# STM32H7B0 register map
File version: 1.7
CPU: CM7 r0p1, little endian, MPU, FPU, 4 interrupt priority bits
Registers are 32-bit, read-write, reset 0x0 unless marked. A register's access mark holds for its fields unless they carry their own. Offsets are from the block's base; [hi:lo] are bit positions; lines under a group give offsets from that group; 'fields as' and 'values as' point back to an identical list.

## Flash (part 2 of 2) — Embedded Flash memory
Base 0x52002000
0x5C FLASH_CRCDATAR — FLASH CRC data register
  [31:0] CRC_DATA — CRC result
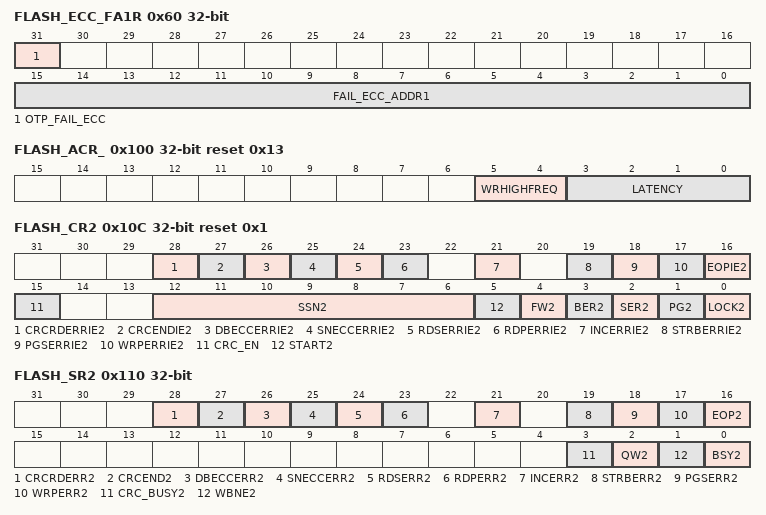
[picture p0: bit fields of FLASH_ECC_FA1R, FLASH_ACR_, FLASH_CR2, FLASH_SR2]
0x60 FLASH_ECC_FA1R ro
  [31] OTP_FAIL_ECC — OTP ECC error bit This bit is set to 1 when one single ECC correction or double ECC detection occurred during the last successful read operation from the read-only/ OTP area. The address of the ECC error is available in FAIL_ECC_ADDR1 bitfield.
  [15:0] FAIL_ECC_ADDR1 — Bank 1 ECC error address When an ECC error occurs (both for single correction or double detection) during a read operation from bank 1, the FAIL_ECC_ADDR1 bitfield contains the address that generated the error. FAIL_ECC_ADDR1 is reset when the flag error in the FLASH_SR1 register (CLR_SNECCERR1 or CLR_DBECCERR1) is reset. The embedded Flash memory programs the address in this register only when no ECC error flags are set. This means that only the first address that generated an ECC error is saved. The address in FAIL_ECC_ADDR1 is relative to the Flash memory area where the error occurred (user Flash memory, system Flash memory, read-only/OTP area).
0x68 FLASH_OTPBL_CUR ro reset not defined — FLASH OTP block lock
  [15:0] LOCKBL — OTP Block Lock Block n corresponds to OTP 16-bit word 32 x n to 32 x n + 31. LOCKBL[n] = 1 indicates that all OTP 16-bit words in OTP Block n are locked and can no longer be programmed. LOCKBL[n] = 0 indicates that all OTP 16-bit words in OTP Block n are not locked and can still be modified.
0x6C FLASH_OTPBL_PRG reset not defined — FLASH OTP block lock
  [15:0] LOCKBL — OTP Block Lock Block n corresponds to OTP 16-bit word 32 x n to 32 x n + 31. LOCKBL[n] = 1 indicates that all OTP 16-bit words in OTP Block n are locked and can no longer be programmed. LOCKBL[n] = 0 indicates that all OTP 16-bit words in OTP Block n are not locked and can still be modified. LOCKBL bits can be set if the corresponding bit in FLASH_OTPBL_CUR is cleared.
0x100 FLASH_ACR_ reset 0x13 — Access control register
  [5:4] WRHIGHFREQ — Flash signal delay
  [3:0] LATENCY — Read latency
0x104 FLASH_KEYR2 wo — FLASH key register for bank 2
  [31:0] KEY2R — Bank 2 access configuration unlock key
0x108 FLASH_OPTKEYR_ — FLASH option key register
  [31:0] OPTKEYR — Unlock key option bytes
0x10C FLASH_CR2 reset 0x1 — FLASH control register for bank 2
  [28] CRCRDERRIE2 — Bank 2 CRC read error interrupt enable bit When CRCRDERRIE2 bit is set to 1, an interrupt is generated when a protected area (PCROP or secure-only) has been detected during the last CRC computation on bank 2. CRCRDERRIE2 can be programmed only when LOCK2 is cleared to 0.
    0=no interrupt generated when a CRC read error occurs on bank 2; 1=interrupt generated when a CRC read error occurs on bank 2
  [27] CRCENDIE2 — Bank 2 CRC end of calculation interrupt enable bit When CRCENDIE2 bit is set to 1, an interrupt is generated when the CRC computation has completed on bank 2. CRCENDIE2 can be programmed only when LOCK2 is cleared to 0.
    0=no interrupt generated when CRC computation complete on bank 2; 1=interrupt generated when CRC computation complete on bank 2
  [26] DBECCERRIE2 — Bank 2 ECC double detection error interrupt enable bit When DBECCERRIE2 bit is set to 1, an interrupt is generated when an ECC double detection error occurs during a read operation from bank 2. DBECCERRIE2 can be programmed only when LOCK2 is cleared to 0.
    0=no interrupt generated when an ECC double detection error occurs on bank 2; 1=interrupt generated if an ECC double detection error occurs on bank 2
  [25] SNECCERRIE2 — Bank 2 ECC single correction error interrupt enable bit When SNECCERRIE2 bit is set to 1, an interrupt is generated when an ECC single correction error occurs during a read operation from bank 2. SNECCERRIE2 can be programmed only when LOCK2 is cleared to 0.
    0=no interrupt generated when an ECC single correction error occurs on bank 2; 1=interrupt generated when an ECC single correction error occurs on bank 2
  [24] RDSERRIE2 — Bank 2 secure error interrupt enable bit When RDSERRIE2 bit is set to 1, an interrupt is generated when a secure error (access to a secure-only protected address) occurs during a read operation from bank 2. RDSERRIE2 can be programmed only when LOCK2 is cleared to 0.
    0=no interrupt generated when a secure error occurs on bank 2; 1=an interrupt is generated when a secure error occurs on bank 2
  [23] RDPERRIE2 — Bank 2 read protection error interrupt enable bit When RDPERRIE2 bit is set to 1, an interrupt is generated when a read protection error occurs (access to an address protected by PCROP or by RDP level 1) during a read operation from bank 2. RDPERRIE2 can be programmed only when LOCK2 is cleared to 0.
    0=no interrupt generated when a read protection error occurs on bank 2; 1=an interrupt is generated when a read protection error occurs on bank 2
  [21] INCERRIE2 — Bank 2 inconsistency error interrupt enable bit When INCERRIE2 bit is set to 1, an interrupt is generated when an inconsistency error occurs during a write operation to bank 2. INCERRIE2 can be programmed only when LOCK2 is cleared to 0.
    0=no interrupt generated when a inconsistency error occurs on bank 2; 1=interrupt generated when a inconsistency error occurs on bank 2
  [19] STRBERRIE2 — Bank 2 strobe error interrupt enable bit When STRBERRIE2 bit is set to 1, an interrupt is generated when a strobe error occurs (the master programs several times the same byte in the write buffer) during a write operation to bank 2. STRBERRIE2 can be programmed only when LOCK2 is cleared to 0.
    0=no interrupt generated when a strobe error occurs on bank 2; 1=interrupt generated when strobe error occurs on bank 2
  [18] PGSERRIE2 — Bank 2 programming sequence error interrupt enable bit When PGSERRIE2 bit is set to 1, an interrupt is generated when a sequence error occurs during a program operation to bank 2. PGSERRIE2 can be programmed only when LOCK2 is cleared to 0.
    0=no interrupt generated when a sequence error occurs on bank 2; 1=interrupt generated when sequence error occurs on bank 2
  [17] WRPERRIE2 — Bank 2 write protection error interrupt enable bit When WRPERRIE2 bit is set to 1, an interrupt is generated when a protection error occurs during a program operation to bank 2. WRPERRIE2 can be programmed only when LOCK2 is cleared to 0.
    0=no interrupt generated when a protection error occurs on bank 2; 1=interrupt generated when a protection error occurs on bank 2
  [16] EOPIE2 — Bank 2 end-of-program interrupt control bit Setting EOPIE2 bit to 1 enables the generation of an interrupt at the end of a program operation to bank 2. EOPIE2 can be programmed only when LOCK2 is cleared to 0.
    0=no interrupt generated at the end of a program operation to bank 2; 1=interrupt enabled when at the end of a program operation to bank 2
  [15] CRC_EN — Bank 2 CRC control bit Setting CRC_EN bit to 1 enables the CRC calculation on bank 2. CRC_EN does not start CRC calculation but enables CRC configuration through FLASH_CRCCR2 register. When CRC calculation is performed on bank 2, it can only be disabled by setting CRC_EN bit to 0. Resetting CRC_EN clears CRC configuration and resets the content of FLASH_CRCDATAR register. CRC_EN can be programmed only when LOCK2 is cleared to 0.
  [12:6] SSN2 — Bank 2 sector erase selection number These bits are used to select the target sector for an erase operation (they are unused otherwise). SSN2 can be programmed only when LOCK2 is cleared to 0. ... ... Note: Bank 2 is limited to 64 sectors on STM32H7A3xG devices.
    0=Sector 0 of user Flash bank 2 selected; 1=Sector 1of user Flash bank 2 selected; 63=Sector 63 of user Flash bank 2 selected; 127=Sector 127 of user Flash bank 2 selected
  [5] START2 — Bank 2 erase start control bit START2 bit is used to start a sector erase or a bank erase operation. START2 can be programmed only when LOCK2 is cleared to 0. The embedded Flash memory resets START2 when the corresponding operation has been acknowledged. The user application cannot access any embedded Flash memory register until the operation is acknowledged.
  [4] FW2 — Bank 2 write forcing control bit FW2 forces a write operation even if the write buffer is not full. FW2 can be programmed only when LOCK2 is cleared to 0. The embedded Flash memory resets FW2 when the corresponding operation has been acknowledged. Write forcing is effective only if the write buffer is not empty. In particular, FW2 does not start several write operations when the write operations are performed consecutively.
  [3] BER2 — Bank 2 erase request Setting BER2 bit to 1 requests a bank erase operation on bank 2 (user Flash memory only). BER2 can be programmed only when LOCK2 is cleared to 0. BER2 has a higher priority than SER2: if both are set, the embedded Flash memory executes a bank erase. Note: Write protection error is triggered when a bank erase is required and some sectors are protected.
    0=bank erase not requested on bank 2; 1=bank erase requested on bank 2
  [2] SER2 — Bank 2 sector erase request Setting SER2 bit to 1 requests a sector erase on bank 2. SER2 can be programmed only when LOCK2 is cleared to 0. BER2 has a higher priority than SER2: if both are set, the embedded Flash memory executes a bank erase. Note: Write protection error is triggered when a sector erase is required on protected sector(s).
    0=sector erase not requested on bank 2; 1=sector erase requested on bank 2
  [1] PG2 — Bank 2 internal buffer control bit Setting PG2 bit to 1 enables internal buffer for write operations to bank 2. This allows the preparation of program operations even if a sector or bank erase is ongoing. PG2 can be programmed only when LOCK2 is cleared to 0. When PG2 is reset, the internal buffer is disabled for write operations to bank 2 and all the data stored in the buffer but not sent to the operation queue are lost.
  [0] LOCK2 — Bank 2 configuration lock bit This bit locks the FLASH_CR2 register. The correct write sequence to FLASH_KEYR2 register unlocks this bit. If a wrong sequence is executed, or the unlock sequence to FLASH_KEYR2 is performed twice, this bit remains locked until next system reset. LOCK2 can be set by programming it to 1. When set to 1, a new unlock sequence is mandatory to unlock it. When LOCK2 changes from 0 to 1, the other bits of FLASH_CR2 register do not change.
    0=FLASH_CR2 register unlocked; 1=FLASH_CR2 register locked
0x110 FLASH_SR2 ro — FLASH status register for bank 2
  [28] CRCRDERR2 — Bank 2 CRC read error flag CRCRDERR2 flag is raised when a word is found read protected during a CRC operation on bank 2. An interrupt is generated if CRCRDIE2 and CRCEND2 are set to 1. Writing 1 to CLR_CRCRDERR2 bit in FLASH_CCR2 register clears CRCRDERR2. Note: This flag is valid only when CRCEND2 bit is set to 1.
    0=no protected area inside the address read by CRC on bank 2; 1=a protected area inside the address read by CRC on bank 2. CRC result is very likely incorrect.
  [27] CRCEND2 — Bank 2 CRC end of calculation flag CRCEND2 bit is raised when the CRC computation has completed on bank 2. An interrupt is generated if CRCENDIE2 is set to 1. It is not necessary to reset CRCEND2 before restarting CRC computation. Writing 1 to CLR_CRCEND2 bit in FLASH_CCR2 register clears CRCEND2.
    0=CRC computation not complete on bank 2; 1=CRC computation complete on bank 2
  [26] DBECCERR2 — Bank 2 ECC double detection error flag DBECCERR2 flag is raised when an ECC double detection error occurs during a read operation from bank 2. An interrupt is generated if DBECCERRIE2 is set to 1. Writing 1 to CLR_DBECCERR2 bit in FLASH_CCR2 register clears DBECCERR2.
    0=no ECC double detection error occurs on bank 2; 1=ECC double detection error occurs on bank 2
  [25] SNECCERR2 — Bank 2 single correction error flag SNECCERR2 flag is raised when an ECC single correction error occurs during a read operation from bank 2. An interrupt is generated if SNECCERRIE2 is set to 1. Writing 1 to CLR_SNECCERR2 bit in FLASH_CCR2 register clears SNECCERR2.
    0=no ECC single correction error occurs on bank 2; 1=ECC single correction error occurs on bank 2
  [24] RDSERR2 — Bank 2 secure error flag RDSERR2 flag is raised when a read secure error (read access to a secure-only protected word) occurs on bank 2. An interrupt is generated if RDSERRIE2 is set to 1. Writing 1 to CLR_RDSERR2 bit in FLASH_CCR2 register clears RDSERR2.
    0=no secure error occurs on bank 2; 1=a secure error occurs on bank 2
  [23] RDPERR2 — Bank 2 read protection error flag RDPERR2 flag is raised when a read protection error (read access to a PCROP-protected word or a RDP-protected area) occurs on bank 2. An interrupt is generated if RDPERRIE2 is set to 1. Writing 1 to CLR_RDPERR2 bit in FLASH_CCR2 register clears RDPERR2.
    0=no read protection error occurs on bank 2; 1=a read protection error occurs on bank 2
  [21] INCERR2 — Bank 2 inconsistency error flag INCERR2 flag is raised when a inconsistency error occurs on bank 2. An interrupt is generated if INCERRIE2 is set to 1. Writing 1 to CLR_INCERR2 bit in the FLASH_CCR2 register clears INCERR2.
    0=no inconsistency error occurred on bank 2; 1=an inconsistency error occurred on bank 2
  [19] STRBERR2 — Bank 2 strobe error flag STRBERR2 flag is raised when a strobe error occurs on bank 2 (when the master attempts to write several times the same byte in the write buffer). An interrupt is generated if the STRBERRIE2 bit is set to 1. Writing 1 to CLR_STRBERR2 bit in FLASH_CCR2 register clears STRBERR2.
    0=no strobe error occurred on bank 2; 1=a strobe error occurred on bank 2
  [18] PGSERR2 — Bank 2 programming sequence error flag PGSERR2 flag is raised when a sequence error occurs on bank 2. An interrupt is generated if the PGSERRIE2 bit is set to 1. Writing 1 to CLR_PGSERR2 bit in FLASH_CCR2 register clears PGSERR2.
    0=no sequence error occurred on bank 2; 1=a sequence error occurred on bank 2
  [17] WRPERR2 — Bank 2 write protection error flag WRPERR2 flag is raised when a protection error occurs during a program operation to bank 2. An interrupt is also generated if the WRPERRIE2 is set to 1. Writing 1 to CLR_WRPERR2 bit in FLASH_CCR2 register clears WRPERR2.
    0=no write protection error occurred on bank 2; 1=a write protection error occurred on bank 2
  [16] EOP2 — Bank 2 end-of-program flag EOP2 flag is set when a programming operation to bank 2 completes. An interrupt is generated if the EOPIE2 is set to 1. It is not necessary to reset EOP2 before starting a new operation. EOP2 bit is cleared by writing 1 to CLR_EOP2 bit in FLASH_CCR2 register.
    0=no programming operation completed on bank 2; 1=a programming operation completed on bank 2
  [3] CRC_BUSY2 — Bank 2 CRC busy flag CRC_BUSY2 flag is set when a CRC calculation is ongoing on bank 2. This bit cannot be forced to 0. The user must wait until the CRC calculation has completed or disable CRC computation on bank 2.
    0=no CRC calculation ongoing on bank 2; 1=CRC calculation ongoing on bank 2
  [2] QW2 — Bank 2 wait queue flag QW2 flag is set when a write or erase operation is pending in the command queue buffer of bank 2. It is not possible to know what type of operation is present in the queue. This flag is reset by hardware when all write/erase operations have been executed and thus removed from the waiting queue(s). This bit cannot be forced to 0. It is reset after a deterministic time if no other operations are requested.
    0=no write or erase operation is waiting in the operation queues of bank 2; 1=at least one write or erase operation is pending in the operation queues of bank 2
  [1] WBNE2 — Bank 2 write buffer not empty flag WBNE2 flag is set when embedded Flash memory is waiting for new data to complete the write buffer. In this state the write buffer is not empty. WBNE2 is reset by hardware each time the write buffer is complete or the write buffer is emptied following one of the event below: the application software forces the write operation using FW2 bit in FLASH_CR2 the embedded Flash memory detects an error that involves data loss the application software has disabled write operations in this bank This bit cannot be forced to 0. To reset it, clear the write buffer by performing any of the above listed actions or send the missing data.
    0=write buffer of bank 2 empty or full; 1=write buffer of bank 2 waiting data to complete
  [0] BSY2 — Bank 2 busy flag BSY2 flag is set when an effective write or erase operation is ongoing to bank 2. It is not possible to know what type of operation is being executed. BSY2 cannot be forced to 0. It is automatically reset by hardware every time a step in a write, or erase operation completes.
    0=no write or erase operation is executed on bank 2; 1=a write or an erase operation is being executed on bank 2
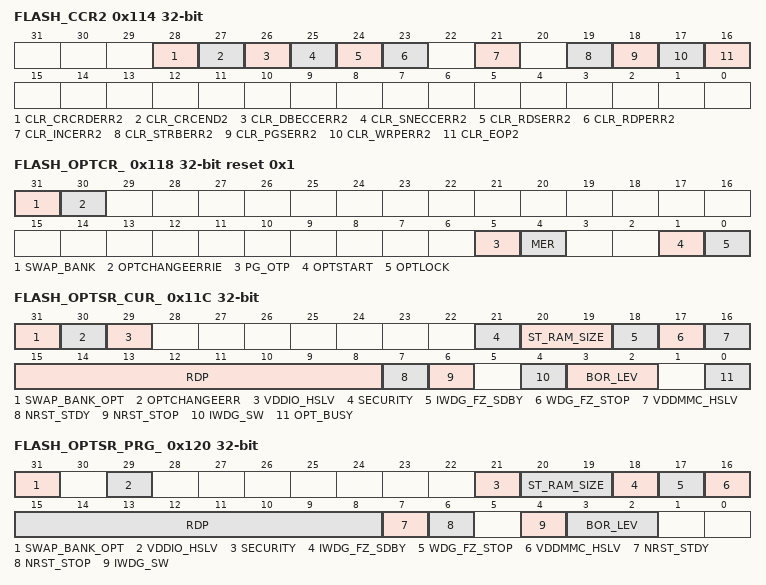
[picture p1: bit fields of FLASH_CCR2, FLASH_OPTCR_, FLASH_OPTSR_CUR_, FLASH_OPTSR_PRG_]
0x114 FLASH_CCR2 wo — FLASH clear control register for bank 2
  [28] CLR_CRCRDERR2 — Bank 2 CRCRDERR2 flag clear bit Setting this bit to 1 resets to 0 CRCRDERR2 flag in FLASH_SR2 register.
  [27] CLR_CRCEND2 — Bank 2 CRCEND2 flag clear bit Setting this bit to 1 resets to 0 CRCEND2 flag in FLASH_SR2 register.
  [26] CLR_DBECCERR2 — Bank 2 DBECCERR2 flag clear bit Setting this bit to 1 resets to 0 DBECCERR2 flag in FLASH_SR2 register. If the SNECCERR2 flag of FLASH_SR2 register is cleared to 0, FLASH_ECC_FA2R register is reset to 0 as well.
  [25] CLR_SNECCERR2 — Bank 2 SNECCERR2 flag clear bit Setting this bit to 1 resets to 0 SNECCERR2 flag in FLASH_SR2 register. If the DBECCERR2 flag of FLASH_SR2 register is cleared to 0, FLASH_ECC_FA2R register is reset to 0 as well.
  [24] CLR_RDSERR2 — Bank 2 RDSERR2 flag clear bit Setting this bit to 1 resets to 0 RDSERR2 flag in FLASH_SR2 register.
  [23] CLR_RDPERR2 — Bank 2 RDPERR2 flag clear bit Setting this bit to 1 resets to 0 RDPERR2 flag in FLASH_SR2 register.
  [21] CLR_INCERR2 — Bank 2 INCERR2 flag clear bit Setting this bit to 1 resets to 0 INCERR2 flag in FLASH_SR2 register.
  [19] CLR_STRBERR2 — Bank 2 STRBERR2 flag clear bit Setting this bit to 1 resets to 0 STRBERR2 flag in FLASH_SR2 register.
  [18] CLR_PGSERR2 — Bank 2 PGSERR2 flag clear bit Setting this bit to 1 resets to 0 PGSERR2 flag in FLASH_SR2 register.
  [17] CLR_WRPERR2 — Bank 2 WRPERR2 flag clear bit Setting this bit to 1 resets to 0 WRPERR2 flag in FLASH_SR2 register.
  [16] CLR_EOP2 — Bank 2 EOP2 flag clear bit Setting this bit to 1 resets to 0 EOP2 flag in FLASH_SR2 register.
0x118 FLASH_OPTCR_ reset 0x1 — FLASH option control register
  [31] SWAP_BANK ro — Bank swapping configuration bit
  [30] OPTCHANGEERRIE — Option byte change error interrupt enable bit
  [5] PG_OTP — OTP program control bit
  [4] MER wo — Flash mass erase enable bit
  [1] OPTSTART wo — Option byte start change option configuration bit
  [0] OPTLOCK — FLASH_OPTCR lock option configuration bit
0x11C FLASH_OPTSR_CUR_ — FLASH option status register
  [31] SWAP_BANK_OPT — Bank swapping option status bit
  [30] OPTCHANGEERR — Option byte change error flag
  [29] VDDIO_HSLV — I/O high-speed at low-voltage status bit (PRODUCT_BELOW_25V)
  [21] SECURITY — Security enable option status bit
  [20:19] ST_RAM_SIZE — DTCM RAM size option status
  [18] IWDG_FZ_SDBY — IWDG Standby mode freeze option status bit
  [17] WDG_FZ_STOP — IWDG Stop mode freeze option status bit
  [16] VDDMMC_HSLV — IWDG Stop mode freeze option status bit
  [15:8] RDP — Readout protection level option status byte
  [7] NRST_STDY — D1 DStandby entry reset option status bit
  [6] NRST_STOP — D1 DStop entry reset option status bit
  [4] IWDG_SW — IWDG1 control option status bit
  [3:2] BOR_LEV — Brownout level option status bit
  [0] OPT_BUSY — Option byte change ongoing flag
0x120 FLASH_OPTSR_PRG_ — FLASH option status register
  [31] SWAP_BANK_OPT — Bank swapping option configuration bit
  [29] VDDIO_HSLV
  [21] SECURITY — Security option configuration bit
  [20:19] ST_RAM_SIZE — DTCM size select option configuration bits
  [18] IWDG_FZ_SDBY — IWDG Standby mode freeze option configuration bit
  [17] WDG_FZ_STOP — IWDG Stop mode freeze option configuration bit
  [16] VDDMMC_HSLV
  [15:8] RDP — Readout protection level option configuration byte
  [7] NRST_STDY — Option byte erase after D1 DStandby option configuration bit
  [6] NRST_STOP — Option byte erase after D1 DStop option configuration bit
  [4] IWDG_SW — IWDG1 option configuration bit
  [3:2] BOR_LEV — BOR reset level option configuration bits
0x124 FLASH_OPTCCR_ wo — FLASH option clear control register
  [30] CLR_OPTCHANGEERR — OPTCHANGEERR reset bit
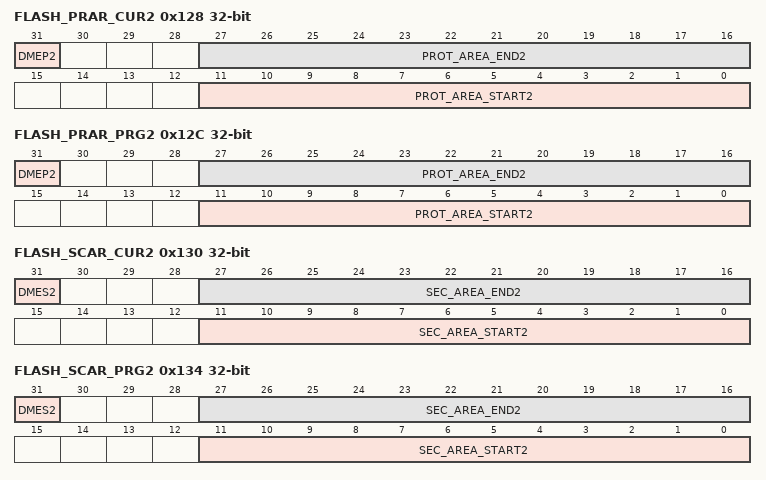
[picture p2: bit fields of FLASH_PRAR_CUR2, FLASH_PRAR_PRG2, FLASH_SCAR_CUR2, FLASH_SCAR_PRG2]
0x128 FLASH_PRAR_CUR2 ro (reset mask 0xF000) — FLASH protection address for bank 2
  [31] DMEP2 — Bank 2 PCROP protected erase enable option status bit If DMEP2 is set to 1, the PCROP protected area in bank 2 is erased when a protection level regression (change from level 1 to 0) or a bank erase with protection removal occurs.
  [27:16] PROT_AREA_END2 — Bank 2 PCROP area end status bits These bits contain the last 256-byte block of the PCROP area in bank 2. If this address is equal to PROT_AREA_START2, the whole bank 2 is PCROP protected. If this address is lower than PROT_AREA_START2, no protection is set on bank 2.
  [11:0] PROT_AREA_START2 — Bank 2 PCROP area start status bits These bits contain the first 256-byte block of the PCROP area in bank 2. If this address is equal to PROT_AREA_END2, the whole bank 2 is PCROP protected. If this address is higher than PROT_AREA_END2, no protection is set on bank 2.
0x12C FLASH_PRAR_PRG2 (reset mask 0xF000) — FLASH protection address for bank 2
  [31] DMEP2 — Bank 2 PCROP protected erase enable option configuration bit If DMEP2 is set to 1, the PCROP protected area in bank 2 is erased when a protection level regression (change from level 1 to 0) or a bank erase with protection removal occurs.
  [27:16] PROT_AREA_END2 — Bank 2 PCROP area end configuration bits These bits contain the last 256-byte block of the PCROP area in bank 2. If this address is equal to PROT_AREA_START2, the whole bank 2 is PCROP protected. If this address is lower than PROT_AREA_START2, no protection is set on bank 2.
  [11:0] PROT_AREA_START2 — Bank 2 PCROP area start configuration bits These bits contain the first 256-byte block of the PCROP area in bank 2. If this address is equal to PROT_AREA_END2, the whole bank 2 is PCROP protected. If this address is higher than PROT_AREA_END2, no protection is set on bank 2.
0x130 FLASH_SCAR_CUR2 ro (reset mask 0xF000) — FLASH secure address for bank 2
  [31] DMES2 — Bank 2 secure protected erase enable option status bit If DMES2 is set to 1, the secure protected area in bank 2 is erased when a protection level regression (change from level 1 to 0) or a bank erase with protection removal occurs.
  [27:16] SEC_AREA_END2 — Bank 2 secure-only area end status bits These bits contain the last 256-byte block of the secure-only area in bank 2. If this address is equal to SEC_AREA_START2, the whole bank 2 is secure protected. If this address is lower than SEC_AREA_START2, no protection is set on bank 2.
  [11:0] SEC_AREA_START2 — Bank 2 secure-only area start status bits These bits contain the first 256-byte block of the secure-only area in bank 2. If this address is equal to SEC_AREA_END2, the whole bank 2 is secure protected. If this address is higher than SEC_AREA_END2, no protection is set on bank 2.
0x134 FLASH_SCAR_PRG2 (reset mask 0xF000) — FLASH secure address for bank 2
  [31] DMES2 — Bank 2 secure access protected erase enable option configuration bit If DMES2 is set to 1, the secure access only area in bank 2 is erased when a protection level regression (change from level 1 to 0) or a bank erase with protection removal occurs.
  [27:16] SEC_AREA_END2 — Bank 2 secure-only area end configuration bits These bits contain the last of 256 bytes block of the secure-only area in bank 2. If this address is equal to SEC_AREA_START2, the whole bank 2 is secure access only. If this address is lower than SEC_AREA_START2, no protection is set on bank 2.
  [11:0] SEC_AREA_START2 — Bank 2 secure-only area start configuration bits These bits contain the first of 256 bytes block of the secure-only area in bank 2. If this address is equal to SEC_AREA_END2, the whole bank 2 is secure access only. If this address is higher than SEC_AREA_END2, no protection is set on bank 2.
0x138 FLASH_WPSGN_CUR2R ro reset not defined — FLASH write sector group protection for bank 2
  [31:0] WRPSGn2 — Bank 2 sector group protection option status byte Each FLASH_WPSGN_CUR2R bit reflects the write protection status of the corresponding group of 4 consecutive sectors in bank 2 (0: group is write protected; 1: group is not write protected) Bit 0: Group embedding sectors 0 to 3 Bit 1: Group embedding sectors 4 to 7 Bit N: Group embedding sectors 4 x N to 4 x N + 3 Bit 31: Group embedding sectors 124 to 127 Note: Bank 2 is limited to 64 sectors on STM32H7A3xG devices.
0x13C FLASH_WPSGN_PRG2R reset not defined — FLASH write sector group protection for bank 2
  [31:0] WRPSGn2 — Bank 2 sector group protection option status byte Setting WRPSGn2 bits to 0 write protects the corresponding group of 4 consecutive sectors in bank 2 (0: group is write protected; 1: group is not write protected) Bit 0: Group embedding sectors 0 to 3 Bit 1: Group embedding sectors 4 to 7 Bit N: Group embedding sectors 4 x N to 4 x N + 3 Bit 31: Group embedding sectors 124 to 127 Note: Bank 2 is limited to 64 sectors on STM32H7A3xG devices.
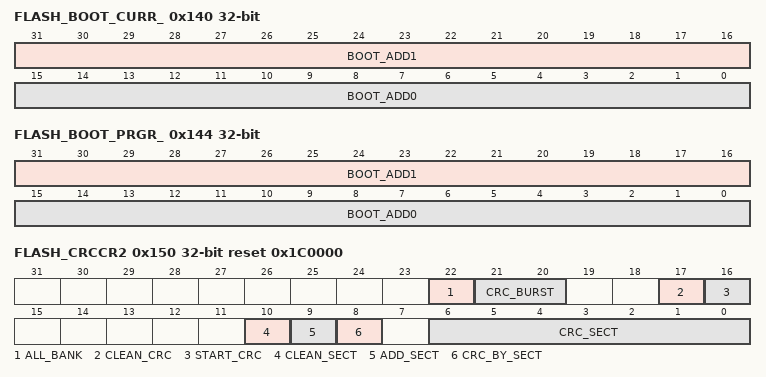
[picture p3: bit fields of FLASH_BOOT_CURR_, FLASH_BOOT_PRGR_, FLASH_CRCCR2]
0x140 FLASH_BOOT_CURR_ ro — FLASH register with boot address
  [31:16] BOOT_ADD1 — Boot address 1
  [15:0] BOOT_ADD0 — Boot address 0
0x144 FLASH_BOOT_PRGR_ ro — FLASH register with boot address
  fields as FLASH_BOOT_CURR_
0x150 FLASH_CRCCR2 access per field reset 0x1C0000 — FLASH CRC control register for bank 2
  [22] ALL_BANK wo — Bank 2 CRC select bit When ALL_BANK is set to 1, all bank 2 user sectors are added to the list of sectors on which the CRC is calculated.
  [21:20] CRC_BURST rw — Bank 2 CRC burst size CRC_BURST bits set the size of the bursts that are generated by the CRC calculation unit.
    0=every burst has a size of 4 Flash words (128 bit); 1=every burst has a size of 16 Flash words (128-bit); 2=every burst has a size of 64 Flash words (128-bit); 3=every burst has a size of 256 Flash words (128-bit)
  [17] CLEAN_CRC wo — Bank 2 CRC clear bit Setting CLEAN_CRC to 1 clears the current CRC result stored in the FLASH_CRCDATAR register.
  [16] START_CRC wo — Bank 2 CRC start bit START_CRC bit triggers a CRC calculation on bank 2 using the current configuration. It is not possible to start a CRC calculation when an option byte change operation is ongoing because all write accesses to embedded Flash memory registers are put on hold until the option byte change operation has completed.
  [10] CLEAN_SECT wo — Bank 2 CRC sector list clear bit Setting CLEAN_SECT to 1 clears the list of sectors on which the CRC is calculated.
  [9] ADD_SECT wo — Bank 2 CRC sector select bit Setting ADD_SECT to 1 adds the sector whose number is CRC_SECT to the list of sectors on which the CRC is calculated.
  [8] CRC_BY_SECT rw — Bank 2 CRC sector mode select bit When CRC_BY_SECT is set to 1, the CRC calculation is performed at sector level, on the sectors selected by CRC_SECT. When CRC_BY_SECT is reset to 0, the CRC calculation is performed on all addresses between CRC_START_ADDR and CRC_END_ADDR.
  [6:0] CRC_SECT rw — Bank 2 CRC sector number CRC_SECT is used to select one or more user Flash sectors to be added to CRC calculation. The CRC can be computed either between two addresses (using registers FLASH_CRCSADD2R and FLASH_CRCEADD2R) or on a list of sectors using this register. If this latter option is selected, it is possible to add a sector to the list of sectors by programming the sector number in CRC_SECT and then setting ADD_SECT to 1. The list of sectors can be erased either by setting CLEAN_SECT bit or by disabling the CRC computation. CRC_SECT can be set only when CRC_EN of FLASH_CR register is set to 1. ... ... Note: Bank 2 is limited to 64 sectors on STM32H7AxG devices.
    0=sector 0 of bank 2 for CRC; 1=sector 1 of bank 2 for CRC; 63=sector 63 of bank 2 for CRC; 127=sector 127 of bank 2 for CRC
0x154 FLASH_CRCSADD2R — FLASH CRC start address register for bank 2
  [19:2] CRC_START_ADDR — CRC start address on bank 2 CRC_START_ADDR is used when CRC_BY_SECT is cleared to 0. It must be programmed to the start address of the bank 2 memory area on which the CRC calculation is performed.
0x158 FLASH_CRCEADD2R — FLASH CRC end address register for bank 2
  [19:2] CRC_END_ADDR — CRC end address on bank 2 CRC_END_ADDR is used when CRC_BY_SECT is cleared to 0. It must be programmed to the end address of the bank 2 memory area on which the CRC calculation is performed.
0x160 FLASH_ECC_FA2R ro — FLASH ECC fail address for bank 2
  [15:0] FAIL_ECC_ADDR2 — Bank 2 ECC error address When an ECC error occurs (both for single error correction or double detection) during a read operation from bank 2, the FAIL_ECC_ADDR2 bitfield contains the address that generated the error. FAIL_ECC_ADDR2 is reset when the flag error in the FLASH_SR2 register (CLR_SNECCERR2 or CLR_DBECCERR2) is reset. The embedded Flash memory programs the address in this register only when no ECC error flags are set. This means that only the first address that generated an ECC error is saved.
